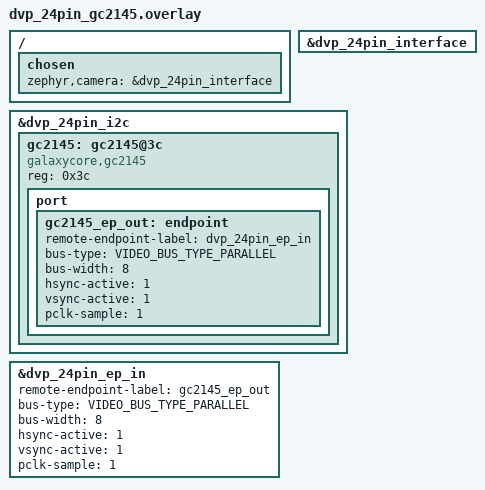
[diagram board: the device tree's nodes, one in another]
/*
 * SPDX-FileCopyrightText: Copyright Panoramix Labs
 * SPDX-License-Identifier: Apache-2.0
 */

#include <zephyr/dt-bindings/video/video-interfaces.h>

/ {
	chosen {
		zephyr,camera = &dvp_24pin_interface;
	};
};

&dvp_24pin_interface {
	status = "okay";
};

&dvp_24pin_i2c {
	status = "okay";

	gc2145: gc2145@3c {
		compatible = "galaxycore,gc2145";
		reg = <0x3c>;
		status = "okay";

		port {
			gc2145_ep_out: endpoint {
				remote-endpoint-label = "dvp_24pin_ep_in";
				bus-type = <VIDEO_BUS_TYPE_PARALLEL>;
				bus-width = <8>;
				hsync-active = <1>;
				vsync-active = <1>;
				pclk-sample = <1>;
			};
		};
	};
};

&dvp_24pin_ep_in {
	remote-endpoint-label = "gc2145_ep_out";
	bus-type = <VIDEO_BUS_TYPE_PARALLEL>;
	bus-width = <8>;
	hsync-active = <1>;
	vsync-active = <1>;
	pclk-sample = <1>;
};
